# AVR32DD20 register map
Vendor: Atmel; File version: 1.0
CPU: other r0p0, little endian, no MPU, no FPU, 4 interrupt priority bits
Registers are 8-bit, read-write, reset 0x0 unless marked. A register's access mark holds for its fields unless they carry their own. Offsets are from the block's base; [hi:lo] are bit positions; {n}, {i} and the like mark numbered series.

## GPR — General Purpose Registers
Base 0x0000001C
{0x0+i} GPR{i} (i=0..3) — General Purpose Register {i}

## LOCK — Lockbits
Base 0x00001040
0x00 KEY 32-bit (reset mask 0xFF) — Lock Key Bits
  [31:0] KEY — Lock Key
    0x5CC5C55C=NOLOCK (No locks); 0xA33A3AA3=RWLOCK (Read and write lock)

## MVIO — Multi-Voltage I/O
Base 0x000000C0
0x00 INTCTRL — Interrupt Control
  [0] VDDIO2IE — VDDIO2 Interrupt Enable
0x01 INTFLAGS — Interrupt Flags
  [0] VDDIO2IF — VDDIO2 Interrupt Flag
0x02 STATUS ro
  [0] VDDIO2S — VDDIO2 Status

## NVMCTRL — Non-volatile Memory Controller
Base 0x00001000
0x00 CTRLA — Control A
  [6:0] CMD — Command
    0=NONE (No Command); 1=NOOP (No Operation); 2=FLWR (Flash Write); 8=FLPER (Flash Page Erase); 9=FLMPER2 (Flash Multi-Page Erase 2 pages); 10=FLMPER4 (Flash Multi-Page Erase 4 pages); 11=FLMPER8 (Flash Multi-Page Erase 8 pages); 12=FLMPER16 (Flash Multi-Page Erase 16 pages); 13=FLMPER32 (Flash Multi-Page Erase 32 pages); 18=EEWR (EEPROM Write); 19=EEERWR (EEPROM Erase and Write); 24=EEBER (EEPROM Byte Erase); 25=EEMBER2 (EEPROM Multi-Byte Erase 2 bytes); 26=EEMBER4 (EEPROM Multi-Byte Erase 4 bytes); 27=EEMBER8 (EEPROM Multi-Byte Erase 8 bytes); 28=EEMBER16 (EEPROM Multi-Byte Erase 16 bytes); 29=EEMBER32 (EEPROM Multi-Byte Erase 32 bytes); 32=CHER (Chip Erase Command); 48=EECHER (EEPROM Erase Command)
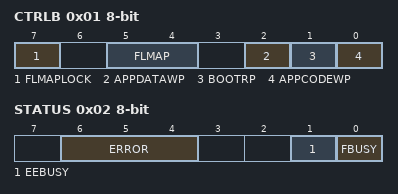
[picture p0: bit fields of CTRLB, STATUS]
0x01 CTRLB — Control B
  [7] FLMAPLOCK — Flash Mapping Lock
  [5:4] FLMAP — Flash Mapping in Data space
    {v}=SECTION{v} (Flash section {v}) (v=0..3)
  [2] APPDATAWP — Application Data Write Protect
  [1] BOOTRP — Boot Read Protect
  [0] APPCODEWP — Application Code Write Protect
0x02 STATUS ro
  [6:4] ERROR — Write error
    0=NOERROR; 1=ILLEGALCMD (Write command not selected); 2=ILLEGALSADDR (Write to section not allowed); 3=DOUBLESELECT (Selecting new write command while write command already seleted); 4=ONGOINGPROG (Starting a new programming operation before previous is completed)
  [1] EEBUSY — EEPROM busy
  [0] FBUSY — Flash busy
0x03 INTCTRL — Interrupt Control
  [0] EEREADY — EEPROM Ready
0x04 INTFLAGS — Interrupt Flags
  [0] EEREADY — EEPROM Ready
0x06 DATA 16-bit (reset mask 0xFF)
0x08 ADDR 32-bit (reset mask 0xFF) — Address

## PORTMUX — Port Multiplexer
Base 0x000005E0
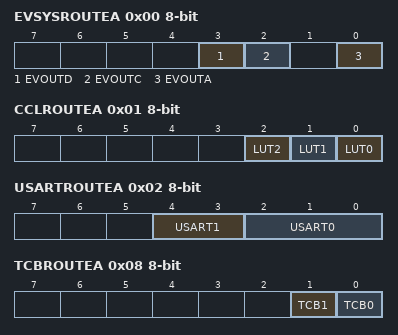
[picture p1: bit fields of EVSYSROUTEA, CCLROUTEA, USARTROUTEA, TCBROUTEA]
0x00 EVSYSROUTEA
  [3] EVOUTD — Event Output D
    0=DEFAULT (Not connected to any pins); 1=ALT1 (EVOUTD: PD7)
  [2] EVOUTC — Event Output C
    0=DEFAULT (EVOUTC: PC2)
  [0] EVOUTA — Event Output A
    0=DEFAULT (EVOUTA: PA2); 1=ALT1 (EVOUTA: PA7)
0x01 CCLROUTEA
  [2] LUT2 — CCL Look-Up Table 2 Signals
    0=DEFAULT (Not connected to any pins); 1=ALT1 (INn: -, -, -. OUT: PD6.)
  [1] LUT1 — CCL Look-Up Table 1 Signals
    0=DEFAULT (INn: -, PC1, PC2 OUT: PC3); 1=ALT1 (INn: -, PC1, PC2 OUT: -)
  [0] LUT0 — CCL Look-Up Table 0 Signals
    0=DEFAULT (INn: PA0, PA1, PA2. OUT: PA3.); 1=ALT1 (INn: PA0, PA1, PA2. OUT: PA6.)
0x02 USARTROUTEA
  [4:3] USART1 — USART1 Signals
    0=DEFAULT (TxD: -, RxD: PC1, XCK: PC2, XDIR: PC3); 2=ALT2 (TxD: PD6, RxD: PD7, XCK: -, XDIR: -); 3=NONE (Not connected to any pins)
  [2:0] USART0 — USART0 Signals
    0=DEFAULT (TxD: PA0, RxD: PA1, XCK: PA2, XDIR: PA3); 1=ALT1 (TxD: PA4, RxD: PA5, XCK: PA6, XDIR: PA7); 2=ALT2 (TxD: PA2, RxD: PA3, XCK: -, XDIR: -); 3=ALT3 (TxD: PD4, RxD: PD5, XCK: PD6, XDIR: PD7); 4=ALT4 (TxD: PC1, RxD: PC2, XCK: PC3, XDIR: -); 5=NONE (Not connected to any pins)
0x05 SPIROUTEA
  [2:0] SPI0 — SPI0 Signals
    0=DEFAULT (MOSI: PA4, MISO: PA5, SCK: PA6, SS: PA7); 3=ALT3 (MOSI: PA0, MISO: PA1, SCK: -, SS: PC1); 4=ALT4 (MOSI: PD4, MISO: PD5, SCK: PD6, SS: PD7); 5=ALT5 (MOSI: -, MISO: PC1, SCK: PC2, SS: PC3); 6=ALT6 (MOSI: PC1, MISO: PC2, SCK: PC3, SS: PF7); 7=NONE (Not connected to any pins. SS set to 1.)
0x06 TWIROUTEA
  [1:0] TWI0 — TWI0 Signals
    0=DEFAULT (SDA: PA2, SCL: PA3. Dual mode: SDA: PC2, SCL: PC3.); 1=ALT1 (SDA: PA2, SCL: PA3. Dual mode: SDA: -, SCL: -.); 2=ALT2 (SDA: PC2, SCL: PC3. Dual mode: SDA: -, SCL: -.); 3=ALT3 (SDA: PA0, SCL: PA1. Dual mode: SDA: PC2, SCL: PC3.)
0x07 TCAROUTEA
  [2:0] TCA0 — TCA0 Signals
    0=PORTA (WOn: PA0, PA1, PA2, PA3, PA4, PA5); 2=PORTC (WOn: -, PC1, PC2, PC3, -, -); 3=PORTD (WOn: -, -, -, -, PD4, PD5)
0x08 TCBROUTEA
  [1] TCB1 — TCB1 Output
    0=DEFAULT (WO: PA3)
  [0] TCB0 — TCB0 Output
    0=DEFAULT (WO: PA2)
0x09 TCDROUTEA
  [2:0] TCD0 — TCD0 Signals
    0=DEFAULT (WOx: PA4, PA5, PA6, PA7); 4=ALT4 (WOx: PA4, PA5, PD4, PD5)
